VERSION ""

NS_ :

BS_:

BU_:

BO_ 3221225472 VECTOR__INDEPENDENT_SIG_MSG: 0 Vector__XXX
 SG_ Motor3High : 32|8@1+ (1,0) [0|0] "" Vector__XXX
 SG_ Motor4Low : 40|8@1+ (1,0) [0|0] "" Vector__XXX
 SG_ Motor4High : 48|8@1+ (1,0) [0|0] "" Vector__XXX
 SG_ Motor4Low2 : 56|8@1+ (1,0) [0|0] "" Vector__XXX
 SG_ Motor2Low : 8|8@1+ (1,0) [0|0] "" Vector__XXX
 SG_ Motor1High : 0|8@1+ (1,0) [0|0] "" Vector__XXX
 SG_ Motor2Low : 24|8@1+ (1,0) [0|0] "" Vector__XXX
 SG_ MotorID8Mode : 56|8@1+ (1,0) [0|0] "" Vector__XXX
 SG_ MotorID7Mode : 48|8@1+ (1,0) [0|0] "" Vector__XXX
 SG_ MotorID6Mode : 40|8@1+ (1,0) [0|0] "" Vector__XXX
 SG_ MotorID5Mode : 32|8@1+ (1,0) [0|0] "" Vector__XXX
 SG_ MotorID4Mode : 24|8@1+ (1,0) [0|0] "" Vector__XXX
 SG_ MotorID3Mode : 16|8@1+ (1,0) [0|0] "" Vector__XXX
 SG_ NewSignal_0001 : 23|8@0+ (1,0) [0|0] "" Vector__XXX

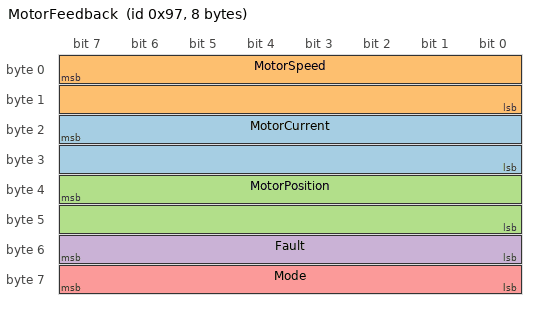
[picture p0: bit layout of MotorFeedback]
BO_ 151 MotorFeedback: 8 Vector__XXX
 SG_ MotorCurrent : 23|16@0- (0.001678467,0) [-55.000006656|54.998328189] "A" Vector__XXX
 SG_ MotorSpeed : 7|16@0- (0.01,0) [-327.68|327.67] "RPM" Vector__XXX
 SG_ MotorPosition : 39|16@0- (0.010986328125,0) [0|360] "Deg" Vector__XXX
 SG_ Fault : 55|8@0+ (1,0) [0|0] "" Vector__XXX
 SG_ Mode : 63|8@0+ (1,0) [0|0] "" Vector__XXX

BO_ 261 ModeSetting: 8 Vector__XXX
 SG_ Motor1 : 0|8@1+ (1,0) [0|0] "" Vector__XXX
 SG_ Motor2 : 8|8@1+ (1,0) [0|0] "" Vector__XXX

BO_ 50 SetPoint: 8 Vector__XXX
 SG_ Setpoint : 7|16@0+ (1,0) [0|65535] "" Vector__XXX

BA_DEF_  "BusType" STRING ;
BA_DEF_DEF_  "BusType" "CAN";
VAL_ 151 Fault 0 "No Fault" 1 "Under Voltage <18V" 2 "Under Voltage <22V" 3 "Over Voltage >63V" 10 "Over Current >20A" 20 "Over Speed" 32 "Over Temp > 80C" 31 "Over Temp >120C" 41 "Sampling Resistor Fault" 42 "Position Sensor Fault" 43 "Position Sensor Interference" 44 "Temperature Sensor Fault" 60 "Communication Timeout" 98 "Stall" ;
VAL_ 151 Mode 0 "Voltage Open Loop" 1 "Current Feedback" 2 "Speed Feedback" 3 "Postion Feedback" 9 "Motor Disabled" 10 "Motor Enabled" ;
VAL_ 261 Motor1 0 "Voltage Open" 1 "Current Control" 2 "Speed Control" 3 "Position Control" 9 "Disable Motor" 10 "Enable Motor" ;
VAL_ 261 Motor2 0 "Voltage Control" 1 "Current Control" 2 "Speed Control" 3 "Position Control" 9 "Disable Motor" 10 "Enable Motor" ;
